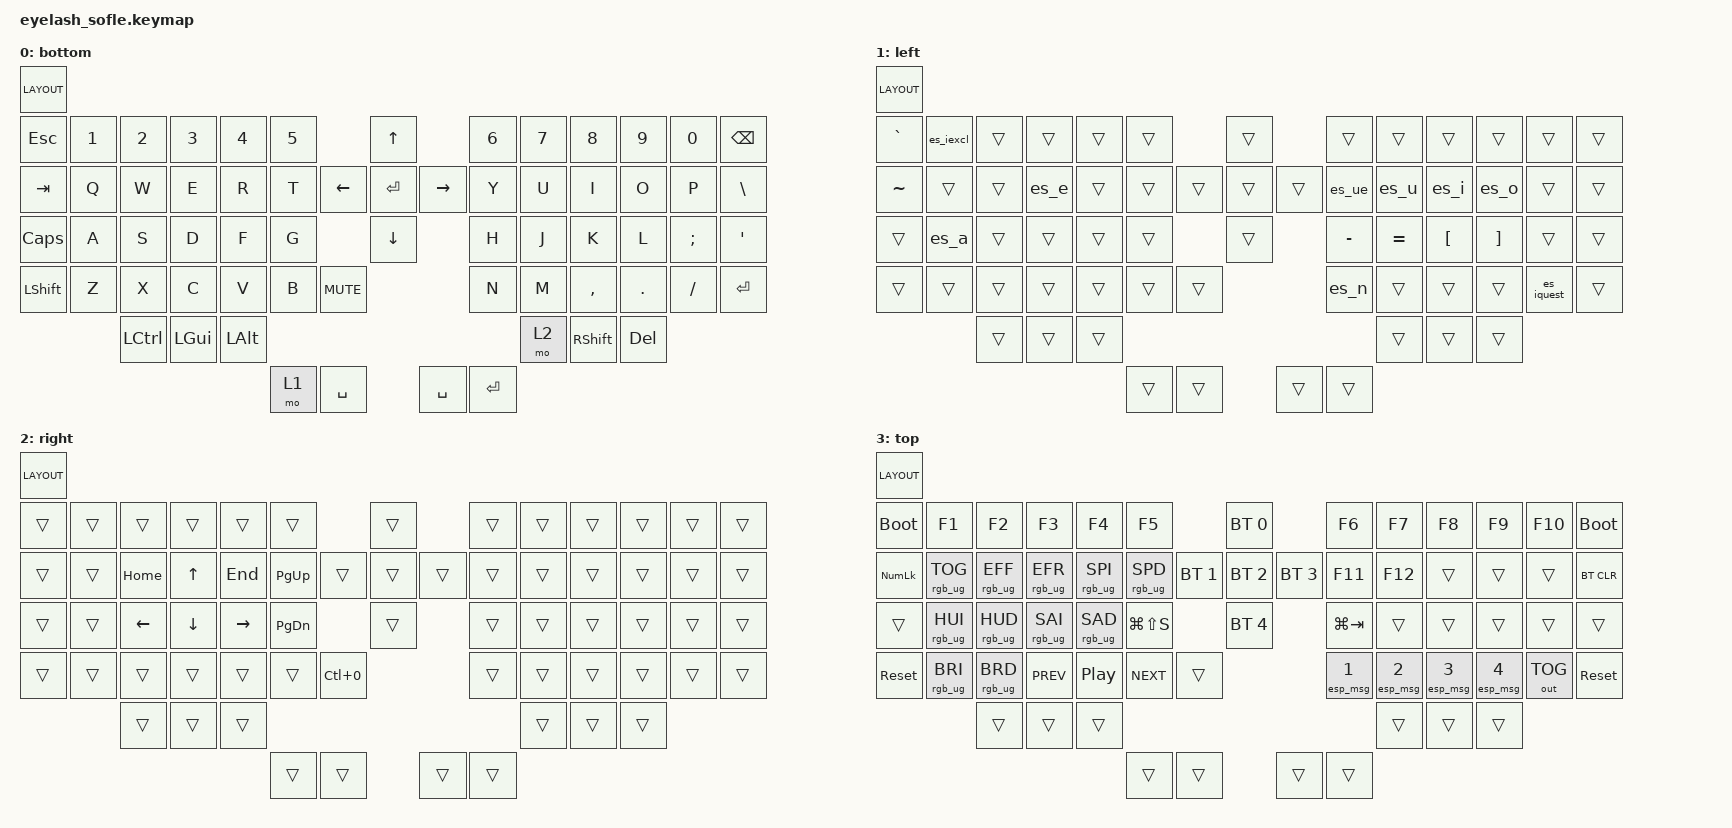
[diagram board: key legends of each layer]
#define ZMK_POINTING_DEFAULT_MOVE_VAL 1200  // 600
#define ZMK_POINTING_DEFAULT_SCRL_VAL 35    // 10

#include <input/processors.dtsi>
#include <zephyr/dt-bindings/input/input-event-codes.h>
#include <behaviors.dtsi>
#include <behaviors/runtime-sensor-rotate.dtsi>
#include <dt-bindings/zmk/bt.h>
#include <dt-bindings/zmk/keys.h>
#include <dt-bindings/zmk/outputs.h>
#include <dt-bindings/zmk/pointing.h>
#include <dt-bindings/zmk/rgb.h>

// LAYOUT: los argumentos se escriben en el orden fisico del dibujo de cada capa
// (banda por banda, de izquierda a derecha) y la macro los reordena al orden
// fila por fila que espera ZMK. kNN = posicion NN en ese orden de ZMK.
#define LAYOUT( \
    k00, k01, k02, k03, k04, k05, k06, k07, k08, k09, k10, k11, k12, k13, k14, k15, k16, k17, k18, k32, k58, k45, k20, k21, k22, k23, k24, k25, k26, k27, k28, k29, k30, k31, k19, k33, k34, k35, k36, k37, k38, k39, k40, k41, k42, k43, k44, k52, k46, k47, k48, k49, k50, k51, k53, k54, k55, k61, k62, k63, k56, k57, k59, k60 \
) \
    k00 k01 k02 k03 k04 k05 k06 k07 k08 k09 k10 k11 k12 k13 k14 k15 k16 k17 k18 k19 k20 k21 k22 k23 k24 k25 k26 k27 k28 k29 k30 k31 k32 k33 k34 k35 k36 k37 k38 k39 k40 k41 k42 k43 k44 k45 k46 k47 k48 k49 k50 k51 k52 k53 k54 k55 k56 k57 k58 k59 k60 k61 k62 k63

// Caracteres en espanol con Windows en ingles (US): se escriben con codigos Alt
// (Alt + 4 digitos del teclado numerico). Requiere Bloq Num activado en Windows.
// Tiempos cortos para que la macro termine antes de soltar la tecla: el mod-morph
// solo oculta el Shift mientras la tecla esta apretada.
#define ALT_CODE(name, a, b, c, d) \
    ZMK_MACRO(name, \
        wait-ms = <2>; \
        tap-ms = <2>; \
        bindings = <&macro_press &kp LALT>, \
                   <&macro_tap &kp KP_N##a &kp KP_N##b &kp KP_N##c &kp KP_N##d>, \
                   <&macro_release &kp LALT>; \
    )

// Minuscula sola, mayuscula con Shift
#define ES_CHAR(name, lower, upper) \
    name: name { \
        compatible = "zmk,behavior-mod-morph"; \
        #binding-cells = <0>; \
        bindings = <&lower>, <&upper>; \
        mods = <(MOD_LSFT|MOD_RSFT)>; \
    };

/ {
    zip_scroll_scaler: zip_scroll_scaler {
        compatible = "zmk,input-processor-scaler";
        #input-processor-cells = <2>;
        type = <INPUT_EV_REL>;
        codes = <INPUT_REL_WHEEL INPUT_REL_HWHEEL>;
        track-remainders;
    };
};

&mmv_input_listener { input-processors = <&zip_xy_scaler 2 1>; };

&msc_input_listener { input-processors = <&zip_scroll_scaler 2 1>; };

&msc {
    acceleration-exponent = <0>;      // 0
    time-to-max-speed-ms = <0>;       // 300
    delay-ms = <0>;                   // 0
};

&mmv {
    time-to-max-speed-ms = <400>;
    acceleration-exponent = <1>;
};

&soft_off { hold-time-ms = <2000>; };

/ {
    scroll_encoder: scroll_encoder {
        compatible = "zmk,behavior-sensor-rotate";
        #sensor-binding-cells = <0>;
        bindings = <&msc SCRL_DOWN>, <&msc SCRL_UP>;

        tap-ms = <100>;
    };

    macros {
        shift_MB3: shift_MB3 {
            compatible = "zmk,behavior-macro";
            #binding-cells = <0>;
            bindings =
                <&macro_press>,
                <&kp LEFT_SHIFT>,
                <&macro_press>,
                <&mkp MB3>,
                <&macro_pause_for_release>,
                <&macro_release>,
                <&mkp MB3 &kp LEFT_SHIFT>;

            label = "SHIFT_MB3";
        };

        ALT_CODE(alt_a_min, 0, 2, 2, 5)   // á
        ALT_CODE(alt_a_may, 0, 1, 9, 3)   // Á
        ALT_CODE(alt_e_min, 0, 2, 3, 3)   // é
        ALT_CODE(alt_e_may, 0, 2, 0, 1)   // É
        ALT_CODE(alt_i_min, 0, 2, 3, 7)   // í
        ALT_CODE(alt_i_may, 0, 2, 0, 5)   // Í
        ALT_CODE(alt_o_min, 0, 2, 4, 3)   // ó
        ALT_CODE(alt_o_may, 0, 2, 1, 1)   // Ó
        ALT_CODE(alt_u_min, 0, 2, 5, 0)   // ú
        ALT_CODE(alt_u_may, 0, 2, 1, 8)   // Ú
        ALT_CODE(alt_ue_min, 0, 2, 5, 2)  // ü
        ALT_CODE(alt_ue_may, 0, 2, 2, 0)  // Ü
        ALT_CODE(alt_n_min, 0, 2, 4, 1)   // ñ
        ALT_CODE(alt_n_may, 0, 2, 0, 9)   // Ñ
        ALT_CODE(es_iexcl, 0, 1, 6, 1)    // ¡
        ALT_CODE(es_iquest, 0, 1, 9, 1)   // ¿
    };

    behaviors {
        hm: homerow_mods {
            compatible = "zmk,behavior-hold-tap";
            #binding-cells = <2>;
            flavor = "balanced";
            tapping-term-ms = <200>;
            quick-tap-ms = <150>;
            require-prior-idle-ms = <150>;
            bindings = <&kp>, <&kp>;
        };

        rsr_vol: rsr_vol {
            compatible = "zmk,behavior-runtime-sensor-rotate";
            #sensor-binding-cells = <0>;
            tap-ms = <5>;
            cw-binding = <&kp C_VOL_UP>;
            ccw-binding = <&kp C_VOL_DN>;
        };

        // Mensajes por BLE para el ESP32 (solo hace algo en el dongle)
        esp_msg: esp_msg {
            compatible = "zmk,behavior-esp-msg";
            #binding-cells = <1>;
            display-name = "ESP32 Msg";
        };

        ES_CHAR(es_a, alt_a_min, alt_a_may)
        ES_CHAR(es_e, alt_e_min, alt_e_may)
        ES_CHAR(es_i, alt_i_min, alt_i_may)
        ES_CHAR(es_o, alt_o_min, alt_o_may)
        ES_CHAR(es_u, alt_u_min, alt_u_may)
        ES_CHAR(es_ue, alt_ue_min, alt_ue_may)
        ES_CHAR(es_n, alt_n_min, alt_n_may)
    };
   combos {
        compatible = "zmk,combos";

        softoff {
            bindings = <&soft_off>;
            key-positions = <14 28 40>;
        };
    };
    conditional_layers {   /* CAPA CONDICIONAL */
        compatible = "zmk,conditional-layers";

        top {
            if-layers = <1 2>;
            then-layer = <3>;
        };
    };

    keymap {
        compatible = "zmk,keymap";

        layer0 {
            bindings = <
            LAYOUT(
            /*+------------+---------+------------+---------------+---------------+---------+                       +-----------------+                        +-----------+---------+------------------+-------------+-----------+----------------+ */
            /*| ESC        | 1       | 2          | 3             | 4             | 5       |                       | ^               |                        | 6         | 7       | 8                | 9           | 0         | BKSP           | */
                &kp ESC,     &kp N1,   &kp N2,      &kp N3,         &kp N4,         &kp N5,                           &kp UP_ARROW,                              &kp N6,     &kp N7,   &kp N8,            &kp N9,       &kp N0,     &kp BACKSPACE,
            /*+------------+---------+------------+---------------+---------------+---------+     +-----------------+-----------------+------------------+     +-----------+---------+------------------+-------------+-----------+----------------+ */
            /*| TAB        | Q       | W          | E             | R             | T       |     | <               | ENTER           | >                |     | Y         | U       | I                | O           | P         | \              | */
                &kp TAB,     &kp Q,    &kp W,       &kp E,          &kp R,          &kp T,          &kp LEFT_ARROW,   &kp ENTER,        &kp RIGHT_ARROW,         &kp Y,      &kp U,    &kp I,             &kp O,        &kp P,      &kp BSLH,
            /*+------------+---------+------------+---------------+---------------+---------+     +-----------------+-----------------+------------------+     +-----------+---------+------------------+-------------+-----------+----------------+ */
            /*| CAPS       | A       | S          | D             | F             | G       |                       | v               |                        | H         | J       | K                | L           | ;         | '              | */
                &kp CAPS,    &kp A,    &kp S,       &kp D,          &kp F,          &kp G,                            &kp DOWN_ARROW,                            &kp H,      &kp J,    &kp K,             &kp L,        &kp SEMI,   &kp APOS,
            /*+------------+---------+------------+---------------+---------------+---------+     +-----------------+-----------------+                        +-----------+---------+------------------+-------------+-----------+----------------+ */
            /*| SHIFT      | Z       | X          | C             | V             | B       |     | MUTE            |                                          | N         | M       | ,                | .           | /         | ENTER          | */
                &kp LSHFT,   &kp Z,    &kp X,       &kp C,          &kp V,          &kp B,          &kp C_MUTE,                                                  &kp N,      &kp M,    &kp COMMA,         &kp DOT,      &kp FSLH,   &kp ENTER,
            /*+------------+---------+------------+---------------+---------------+---------+     +-----------------+                                          +-----------+---------+------------------+-------------+-----------+----------------+ */
            /*                       | CTRL       | GUI           | ALT           |                                                                                        | MO2     | SHIFT            | DEL         | */
                                       &kp LCTRL,   &kp LEFT_GUI,   &kp LEFT_ALT,                                                                                            &mo 2,    &kp RIGHT_SHIFT,   &kp DELETE,
            /*                       +------------+---------------+---------------+---------+     +-----------------+                 +------------------+     +-----------+---------+------------------+-------------+ */
            /*                                                                    | MO1     |     | SPACE           |                 | SPACE            |     | ENTER     | */
                                                                                    &mo 1,          &kp SPACE,                          &kp SPACE,               &kp ENTER
            /*                                                                    +---------+     +-----------------+                 +------------------+     +-----------+ */
            )
            >;
            sensor-bindings = <&rsr_vol &rsr_trans>;

            display-name = "bottom";
        };

        layer_1 {
            bindings = <
            LAYOUT(
            /*+--------------+--------------+--------------+--------------+--------------+---------+               +---------+               +---------+---------+---------+---------+---------+---------+ */
            /*| GRAVE        | ¡            | trans        | trans        | trans        | trans   |               | trans   |               | trans   | trans   | trans   | trans   | trans   | trans   | */
                &kp GRAVE,     &es_iexcl,     &trans,        &trans,        &trans,        &trans,                   &trans,                   &trans,   &trans,   &trans,   &trans,   &trans,   &trans,
            /*+--------------+--------------+--------------+--------------+--------------+---------+     +---------+---------+---------+     +---------+---------+---------+---------+---------+---------+ */
            /*| TILDE        | trans        | trans        | é É          | trans        | trans   |     | trans   | trans   | trans   |     | ü Ü     | ú Ú     | í Í     | ó Ó     | trans   | trans   | */
                &kp TILDE,     &trans,        &trans,        &es_e,         &trans,        &trans,         &trans,   &trans,   &trans,         &es_ue,   &es_u,    &es_i,    &es_o,    &trans,   &trans,
            /*+--------------+--------------+--------------+--------------+--------------+---------+     +---------+---------+---------+     +---------+---------+---------+---------+---------+---------+ */
            /*| trans        | á Á          | trans        | trans        | trans        | trans   |               | trans   |               | - _     | = +     | [ {     | ] }     | trans   | trans   | */
                &trans,        &es_a,         &trans,        &trans,        &trans,        &trans,                 &trans,                   &kp MINUS, &kp EQUAL, &kp LBKT, &kp RBKT, &trans,   &trans,
            /*+--------------+--------------+--------------+--------------+--------------+---------+     +---------+---------+               +---------+---------+---------+---------+---------+---------+ */
            /*| trans        | trans        | trans        | trans        | trans        | trans   |     | trans   |                         | ñ Ñ     | trans   | trans   | trans   | ¿       | trans   | */
                &trans,        &trans,        &trans,        &trans,        &trans,        &trans,         &trans,                             &es_n,    &trans,   &trans,   &trans,   &es_iquest, &trans,
            /*+--------------+--------------+--------------+--------------+--------------+---------+     +---------+                         +---------+---------+---------+---------+---------+---------+ */
            /*                              | trans        | trans        | trans        |                                                             | trans   | trans   | trans   | */
                                              &trans,        &trans,        &trans,                                                                      &trans,   &trans,   &trans,
            /*                              +--------------+--------------+--------------+---------+     +---------+         +---------+     +---------+---------+---------+---------+ */
            /*                                                                           | trans   |     | trans   |         | trans   |     | trans   | */
                                                                                           &trans,         &trans,             &trans,         &trans
            /*                                                                           +---------+     +---------+         +---------+     +---------+ */
            )
            >;

            display-name = "left";
            sensor-bindings = <&rsr_vol &rsr_trans>;
            
        };

        layer_2 {
            bindings = <
            LAYOUT(
            /*+---------+---------+---------+---------+---------+---------+                 +---------+               +---------+--------------+--------------+--------------+--------------+---------+ */
            /*| trans   | trans   | trans   | trans   | trans   | trans   |                 | trans   |               | trans   | trans        | trans        | trans        | trans        | trans   | */
                &trans,   &trans,   &trans,   &trans,   &trans,   &trans,                     &trans,                   &trans,   &trans,        &trans,        &trans,        &trans,        &trans,
            /*+---------+---------+---------+---------+---------+---------+     +-----------+---------+---------+     +---------+--------------+--------------+--------------+--------------+---------+ */
            /*| trans   | trans   | HOME    | UP      | END     | PG UP   |     | trans     | trans   | trans   |     | trans   | trans        | trans        | trans        | trans        | trans   | */
                &trans,   &trans,   &kp HOME, &kp UP,   &kp END,  &kp PG_UP,      &trans,     &trans,   &trans,         &trans,   &trans,        &trans,        &trans,        &trans,        &trans,
            /*+---------+---------+---------+---------+---------+---------+     +-----------+---------+---------+     +---------+--------------+--------------+--------------+--------------+---------+ */
            /*| trans   | trans   | LEFT    | DOWN    | RIGHT   | PG DN   |                 | trans   |               | trans   | trans        | trans        | trans        | trans        | trans   | */
                &trans,   &trans,   &kp LEFT, &kp DOWN, &kp RIGHT, &kp PG_DN,                 &trans,                   &trans,   &trans,        &trans,        &trans,        &trans,        &trans,
            /*+---------+---------+---------+---------+---------+---------+     +-----------+---------+               +---------+--------------+--------------+--------------+--------------+---------+ */
            /*| trans   | trans   | trans   | trans   | trans   | trans   |     | ZOOM0     |                         | trans   | trans        | trans        | trans        | trans        | trans   | */
                &trans,   &trans,   &trans,   &trans,   &trans,   &trans,         &kp LC(N0),                           &trans,   &trans,        &trans,        &trans,        &trans,        &trans,
            /*+---------+---------+---------+---------+---------+---------+     +-----------+                         +---------+--------------+--------------+--------------+--------------+---------+ */
            /*                    | trans   | trans   | trans   |                                                               | trans        | trans        | trans        | */
                                    &trans,   &trans,   &trans,                                                                   &trans,        &trans,        &trans,
            /*                    +---------+---------+---------+---------+     +-----------+         +---------+     +---------+--------------+--------------+--------------+ */
            /*                                                  | trans   |     | trans     |         | trans   |     | trans   | */
                                                                  &trans,         &trans,               &trans,         &trans
            /*                                                  +---------+     +-----------+         +---------+     +---------+ */
            )
            >;

            sensor-bindings = <&inc_dec_kp LC(EQUAL) LC(MINUS) &rsr_trans>;

            display-name = "right";
        };

        layer_3 {
            bindings = <
            LAYOUT(
            /*+---------+---------+---------+---------+---------+---------+               +---------+               +------------+---------+---------+-----------+---------+---------+ */
            /*| BOOT    | F1      | F2      | F3      | F4      | F5      |               | BT 1    |               | F6         | F7      | F8      | F9        | F10     | BOOT    | */
                &bootloader, &kp F1, &kp F2,  &kp F3,   &kp F4,   &kp F5,                   &bt BT_SEL 0,             &kp F6,      &kp F7,   &kp F8,   &kp F9,     &kp F10,  &bootloader,
            /*+---------+---------+---------+---------+---------+---------+     +---------+---------+---------+     +------------+---------+---------+-----------+---------+---------+ */
            /*| NUM LK  | RGB TOG | RGB EFF | RGB EFR | SPD UP  | SPD DN  |     | BT 2    | BT 3    | BT 4    |     | F11        | F12     | trans   | trans     | trans   | BT CLR  | */
                &kp KP_NUM, &rgb_ug RGB_TOG, &rgb_ug RGB_EFF, &rgb_ug RGB_EFR, &rgb_ug RGB_SPI, &rgb_ug RGB_SPD, &bt BT_SEL 1, &bt BT_SEL 2, &bt BT_SEL 3, &kp F11, &kp F12, &trans, &trans, &trans, &bt BT_CLR,
            /*+---------+---------+---------+---------+---------+---------+     +---------+---------+---------+     +------------+---------+---------+-----------+---------+---------+ */
            /*| trans   | HUE UP  | HUE DN  | SAT UP  | SAT DN  | CAPTURA |               | BT 5    |               | WIN+TAB    | trans   | trans   | trans     | trans   | trans   | */
                &trans,   &rgb_ug RGB_HUI, &rgb_ug RGB_HUD, &rgb_ug RGB_SAI, &rgb_ug RGB_SAD, &kp LG(LS(S)),            &bt BT_SEL 4,             &kp LG(TAB), &trans,   &trans,   &trans,     &trans,   &trans,
            /*+---------+---------+---------+---------+---------+---------+     +---------+---------+               +------------+---------+---------+-----------+---------+---------+ */
            /*| RESET   | BRT UP  | BRT DN  | PREV    | PLAY    | NEXT    |     | trans   |                         | ESP 1      | ESP 2   | ESP 3   | ESP 4     | USB/BT  | RESET   | */
                &sys_reset, &rgb_ug RGB_BRI, &rgb_ug RGB_BRD, &kp C_PREV, &kp C_PP, &kp C_NEXT, &trans,                     &esp_msg 1,  &esp_msg 2, &esp_msg 3, &esp_msg 4, &out OUT_TOG, &sys_reset,
            /*+---------+---------+---------+---------+---------+---------+     +---------+                         +------------+---------+---------+-----------+---------+---------+ */
            /*                    | trans   | trans   | trans   |                                                                | trans   | trans   | trans     | */
                                    &trans,   &trans,   &trans,                                                                    &trans,   &trans,   &trans,
            /*                    +---------+---------+---------+---------+     +---------+         +---------+     +------------+---------+---------+-----------+ */
            /*                                                  | trans   |     | trans   |         | trans   |     | trans      | */
                                                                  &trans,         &trans,             &trans,         &trans
            /*                                                  +---------+     +---------+         +---------+     +------------+ */
            )
            >;

            display-name = "top";
        };
    };
};



